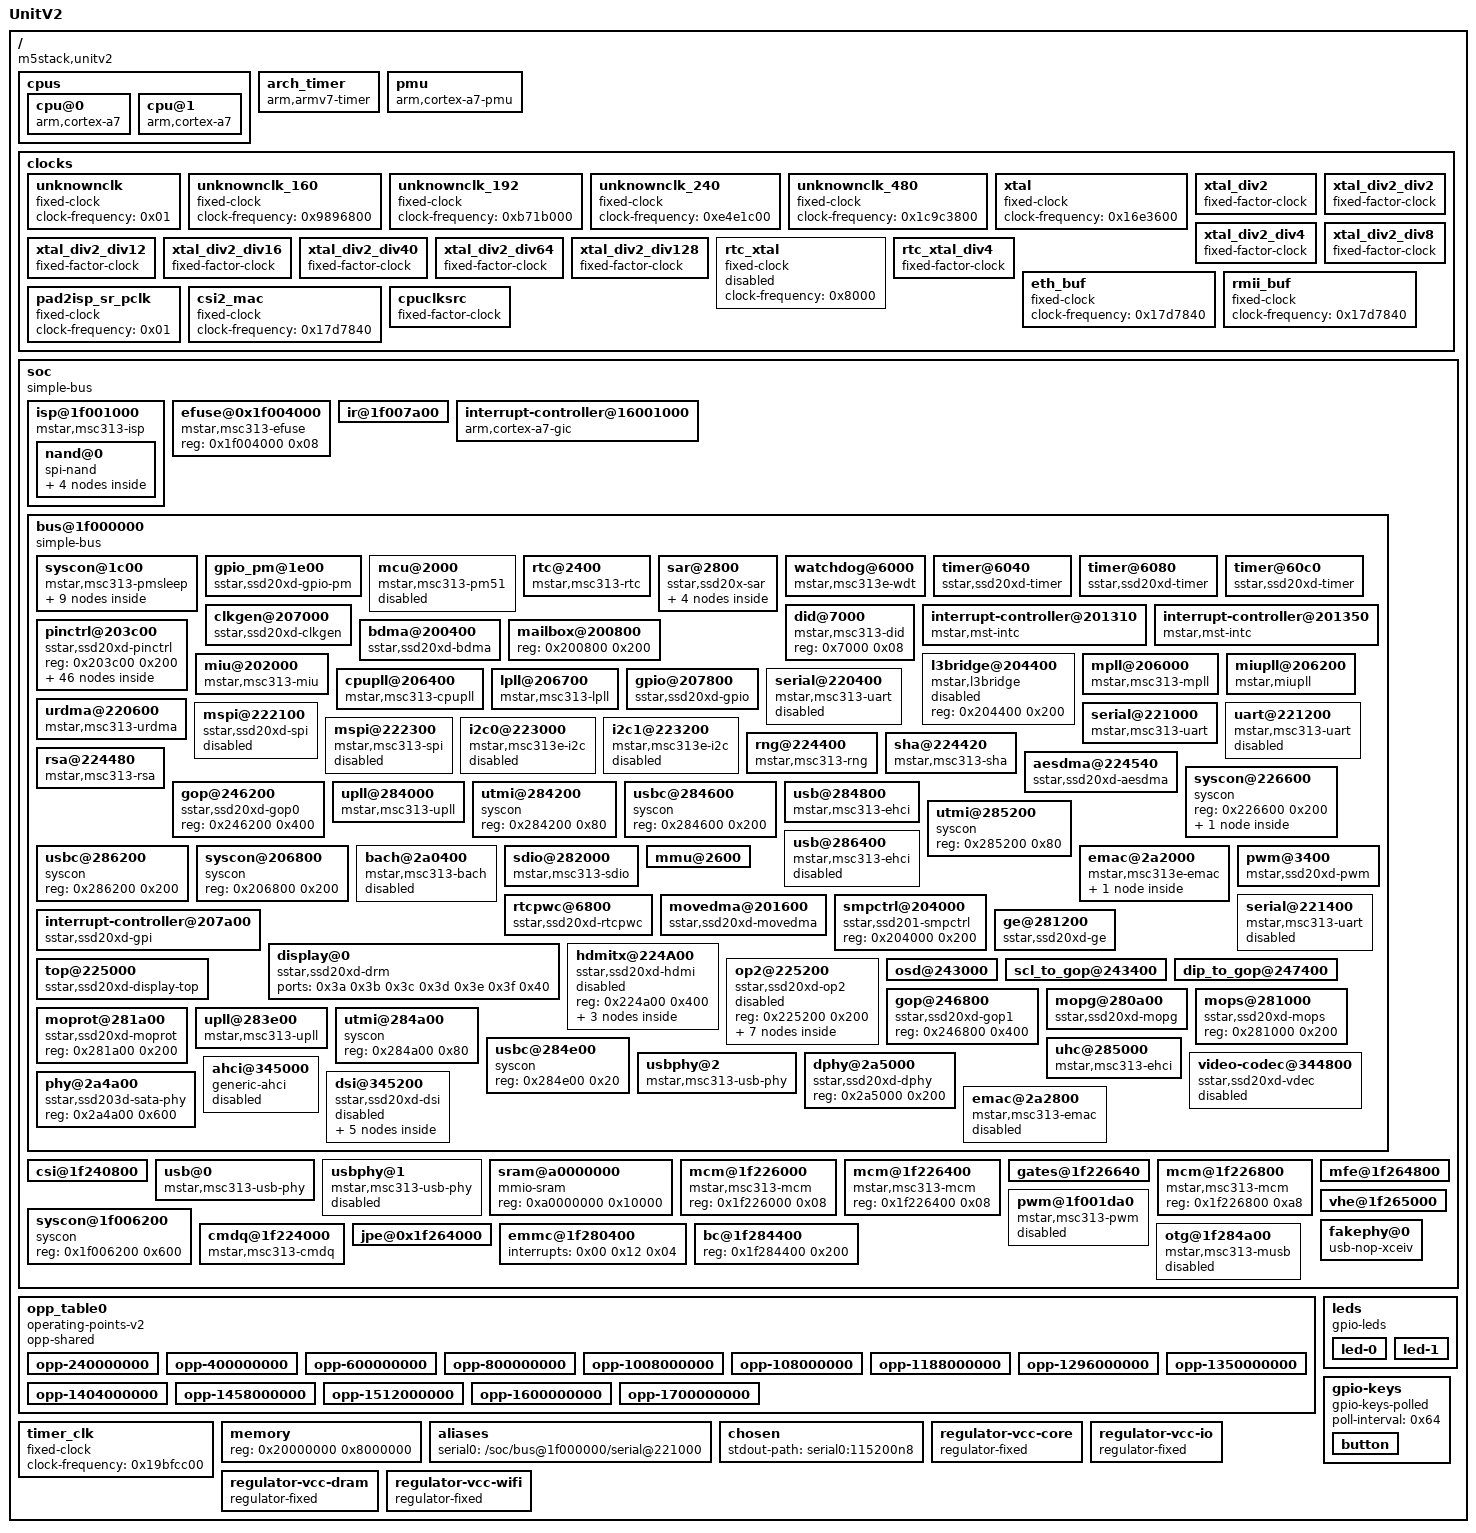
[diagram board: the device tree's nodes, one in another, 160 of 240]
/dts-v1/;

/ {
	#address-cells = <0x01>;
	#size-cells = <0x01>;
	interrupt-parent = <0x01>;
	model = "UnitV2";
	compatible = "m5stack,unitv2\0mstar,infinity2m";

	cpus {
		#address-cells = <0x01>;
		#size-cells = <0x00>;

		cpu@0 {
			device_type = "cpu";
			compatible = "arm,cortex-a7";
			reg = <0x00>;
			clocks = <0x02>;
			clock-names = "cpuclk";
			operating-points-v2 = <0x03>;
			cpu-supply = <0x04>;
			phandle = <0x05>;
		};

		cpu@1 {
			device_type = "cpu";
			compatible = "arm,cortex-a7";
			operating-points-v2 = <0x03>;
			reg = <0x01>;
			clocks = <0x02>;
			clock-names = "cpuclk";
			phandle = <0x06>;
		};
	};

	arch_timer {
		compatible = "arm,armv7-timer";
		interrupts = <0x01 0x0d 0x308 0x01 0x0e 0x308 0x01 0x0b 0x308 0x01 0x0a 0x308>;
		clock-frequency = <0x5b8d80>;
		arm,cpu-registers-not-fw-configured;
	};

	pmu {
		compatible = "arm,cortex-a7-pmu";
		interrupts = <0x00 0x0a 0x04 0x00 0x10 0x04>;
		interrupt-affinity = <0x05 0x06>;
	};

	clocks {

		unknownclk {
			#clock-cells = <0x00>;
			compatible = "fixed-clock";
			clock-frequency = <0x01>;
			phandle = <0x22>;
		};

		unknownclk_160 {
			#clock-cells = <0x00>;
			compatible = "fixed-clock";
			clock-frequency = <0x9896800>;
			phandle = <0x1e>;
		};

		unknownclk_192 {
			#clock-cells = <0x00>;
			compatible = "fixed-clock";
			clock-frequency = <0xb71b000>;
			phandle = <0x1f>;
		};

		unknownclk_240 {
			#clock-cells = <0x00>;
			compatible = "fixed-clock";
			clock-frequency = <0xe4e1c00>;
			phandle = <0x20>;
		};

		unknownclk_480 {
			#clock-cells = <0x00>;
			compatible = "fixed-clock";
			clock-frequency = <0x1c9c3800>;
			phandle = <0x21>;
		};

		xtal {
			#clock-cells = <0x00>;
			compatible = "fixed-clock";
			clock-frequency = <0x16e3600>;
			phandle = <0x07>;
		};

		xtal_div2 {
			#clock-cells = <0x00>;
			compatible = "fixed-factor-clock";
			clocks = <0x07>;
			clock-div = <0x02>;
			clock-mult = <0x01>;
			phandle = <0x08>;
		};

		xtal_div2_div2 {
			compatible = "fixed-factor-clock";
			#clock-cells = <0x00>;
			clocks = <0x08>;
			clock-div = <0x02>;
			clock-mult = <0x01>;
		};

		xtal_div2_div4 {
			compatible = "fixed-factor-clock";
			#clock-cells = <0x00>;
			clocks = <0x08>;
			clock-div = <0x04>;
			clock-mult = <0x01>;
		};

		xtal_div2_div8 {
			compatible = "fixed-factor-clock";
			#clock-cells = <0x00>;
			clocks = <0x08>;
			clock-div = <0x08>;
			clock-mult = <0x01>;
			phandle = <0x15>;
		};

		xtal_div2_div12 {
			compatible = "fixed-factor-clock";
			#clock-cells = <0x00>;
			clocks = <0x08>;
			clock-div = <0x0c>;
			clock-mult = <0x01>;
			phandle = <0x16>;
		};

		xtal_div2_div16 {
			compatible = "fixed-factor-clock";
			#clock-cells = <0x00>;
			clocks = <0x08>;
			clock-div = <0x10>;
			clock-mult = <0x01>;
			phandle = <0x17>;
		};

		xtal_div2_div40 {
			compatible = "fixed-factor-clock";
			#clock-cells = <0x00>;
			clocks = <0x08>;
			clock-div = <0x28>;
			clock-mult = <0x01>;
			phandle = <0x1c>;
		};

		xtal_div2_div64 {
			compatible = "fixed-factor-clock";
			#clock-cells = <0x00>;
			clocks = <0x08>;
			clock-div = <0x40>;
			clock-mult = <0x01>;
		};

		xtal_div2_div128 {
			compatible = "fixed-factor-clock";
			#clock-cells = <0x00>;
			clocks = <0x08>;
			clock-div = <0x80>;
			clock-mult = <0x01>;
		};

		rtc_xtal {
			#clock-cells = <0x00>;
			compatible = "fixed-clock";
			clock-frequency = <0x8000>;
			status = "disabled";
			phandle = <0x09>;
		};

		rtc_xtal_div4 {
			compatible = "fixed-factor-clock";
			#clock-cells = <0x00>;
			clocks = <0x09>;
			clock-div = <0x04>;
			clock-mult = <0x01>;
			phandle = <0x14>;
		};

		eth_buf {
			#clock-cells = <0x00>;
			compatible = "fixed-clock";
			clock-frequency = <0x17d7840>;
			phandle = <0x2c>;
		};

		rmii_buf {
			#clock-cells = <0x00>;
			compatible = "fixed-clock";
			clock-frequency = <0x17d7840>;
			phandle = <0x2d>;
		};

		pad2isp_sr_pclk {
			#clock-cells = <0x00>;
			compatible = "fixed-clock";
			clock-frequency = <0x01>;
		};

		csi2_mac {
			#clock-cells = <0x00>;
			compatible = "fixed-clock";
			clock-frequency = <0x17d7840>;
		};

		cpuclksrc {
			compatible = "fixed-factor-clock";
			#clock-cells = <0x00>;
			clocks = <0x0a 0x01>;
			clock-div = <0x01>;
			clock-mult = <0x01>;
			phandle = <0x0c>;
		};
	};

	soc {
		compatible = "simple-bus";
		#address-cells = <0x01>;
		#size-cells = <0x01>;
		ranges = <0x14000000 0x14000000 0x1000000 0x16001000 0x16001000 0x7000 0x1f000000 0x1f000000 0x400000 0xa0000000 0xa0000000 0x20000>;

		isp@1f001000 {
			#address-cells = <0x01>;
			#size-cells = <0x00>;
			compatible = "mstar,msc313-isp";
			reg = <0x1f001000 0x400 0x1f002c00 0x200 0x1f002e00 0x200 0x14000000 0x1000000>;
			clock-names = "pm_spi\0cpuclk\0spi";
			clocks = <0x0b 0x03 0x0c 0x0d 0x01 0x04 0x00>;
			interrupts-extended = <0x0e 0x00 0x05 0x04>;
			dmas = <0x0f 0x00>;
			dma-names = "qspi";
			pinctrl-names = "default";
			pinctrl-0 = <0x10>;
			status = "okay";
			interconnects = <0x11 0x00>;
			interconnect-names = "dma-mem";

			nand@0 {
				#address-cells = <0x01>;
				#size-cells = <0x01>;
				compatible = "spi-nand";
				reg = <0x00>;
				spi-max-frequency = <0x2625a00>;
				spi-rx-bus-width = <0x04>;

				partitions {
					compatible = "fixed-partitions";
					#address-cells = <0x01>;
					#size-cells = <0x01>;

					uboot-spl@200000 {
						label = "uboot-spl";
						reg = <0x200000 0x60000>;
					};

					ubi@ec0000 {
						label = "ubi";
						reg = <0xec0000 0x60000>;
					};
					data@f20000 {
						label = "data";
						reg = <0xf20000 0x10e0000>;
					};
				};
			};
		};

		efuse@0x1f004000 {
			compatible = "mstar,msc313-efuse";
			reg = <0x1f004000 0x08>;
		};

		ir@1f007a00 {
			interrupts-extended = <0x12 0x00 0x03 0x04 0x12 0x00 0x04 0x04>;
		};

		interrupt-controller@16001000 {
			compatible = "arm,cortex-a7-gic";
			reg = <0x16001000 0x1000 0x16002000 0x2000 0x16004000 0x2000 0x16006000 0x2000>;
			#interrupt-cells = <0x03>;
			interrupt-controller;
			interrupts = <0x01 0x09 0x308>;
			phandle = <0x01>;
		};

		bus@1f000000 {
			compatible = "simple-bus";
			reg = <0x1f000000 0x400000>;
			#address-cells = <0x01>;
			#size-cells = <0x01>;
			ranges = <0x00 0x1f000000 0x400000>;
			interrupts-extended = <0x0e 0x00 0x33 0x04>;

			syscon@1c00 {
				compatible = "mstar,msc313-pmsleep\0syscon\0simple-mfd";
				reg = <0x1c00 0x100>;
				use-raw-spinlock;
				phandle = <0x13>;

				pinctrl {
					compatible = "sstar,ssd20xd-pm-pinctrl";
					phandle = <0x19>;

					pm_uart {
						function = "pm_uart";
						groups = "pm_uart";
						phandle = <0x28>;
					};

					pm_spi {
						function = "pm_spi";
						groups = "pm_spi";
						phandle = <0x10>;
					};

					pm_irin {
						function = "pm_irin";
						groups = "pm_irin";
					};

					pm_led_mode1 {
						function = "pm_led";
						groups = "pm_led_mode1";
					};
				};

				interrupt-controller@1c10 {
					compatible = "mstar,msc313-pm-intc";
					interrupt-parent = <0x0e>;
					interrupts = <0x00 0x02 0x04>;
					interrupt-controller;
					#interrupt-cells = <0x01>;
					phandle = <0x18>;
				};

				interrupt-controller@1c20 {
					compatible = "mstar,msc313-pm-wakeup-intc";
					interrupt-parent = <0x0e>;
					interrupts = <0x00 0x02 0x04>;
					interrupt-controller;
					#interrupt-cells = <0x02>;
					mstar,pmsleep = <0x13>;
					phandle = <0x1a>;
				};

				pm_muxes@0 {
					compatible = "mstar,msc313-pm-muxes";
					#clock-cells = <0x01>;
					clock-names = "rtc_xtal\0rtc_xtal_div4\0xtal_div2\0xtal_div2_div8\0xtal_div2_div12\0xtal_div2_div16\0mpll_div_4";
					clocks = <0x09 0x14 0x08 0x15 0x16 0x17 0x0a 0x03>;
					phandle = <0x0b>;
				};

				reboot {
					compatible = "syscon-reboot";
					offset = <0xb8>;
					mask = <0x79>;
				};
			};

			gpio_pm@1e00 {
				reg = <0x1e00 0x200>;
				#gpio-cells = <0x02>;
				gpio-controller;
				interrupt-controller;
				#interrupt-cells = <0x03>;
				interrupt-parent = <0x18>;
				status = "okay";
				compatible = "sstar,ssd20xd-gpio-pm";
				gpio-ranges = <0x19 0x00 0x20 0x01 0x19 0x01 0x5b 0x01 0x19 0x02 0x67 0x01 0x19 0x02 0x68 0x01>;
				phandle = <0x35>;
			};

			mcu@2000 {
				compatible = "mstar,msc313-pm51";
				reg = <0x2000 0x200>;
				mstar,pmsleep = <0x13>;
				dma-names = "bdma0\0bdma1";
				dmas = <0x0f 0x00 0x0f 0x01>;
				interconnects = <0x11 0x00>;
				interconnect-names = "dma-mem";
				interrupts-extended = <0x12 0x00 0x11 0x04>;
				status = "disabled";
			};

			rtc@2400 {
				compatible = "mstar,msc313-rtc";
				reg = <0x2400 0x40>;
				clocks = <0x0b 0x07>;
				interrupts-extended = <0x0e 0x00 0x2c 0x04 0x1a 0x04 0x04>;
				wakeup-source;
			};

			sar@2800 {
				reg = <0x2800 0x200>;
				interrupts-extended = <0x0e 0x00 0x2d 0x04 0x1a 0x01 0x04 0x1a 0x06 0x04 0x12 0x00 0x18 0x04 0x12 0x00 0x19 0x04 0x12 0x00 0x1a 0x04 0x12 0x00 0x1b 0x04>;
				interrupt-names = "sar\0wakeup\0wakeup_gpio\0sar_gpio0\0sar_gpio1\0sar_gpio2\0sar_gpio3";
				clock-names = "sar_clk";
				clocks = <0x0b 0x09>;
				#gpio-cells = <0x02>;
				mstar,pmsleep = <0x13>;
				wakeup-source;
				status = "okay";
				compatible = "sstar,ssd20x-sar";

				sar0_gpio0 {
					function = "sar0";
					groups = "sar_gpio0";
				};

				sar1_gpio1 {
					function = "sar1";
					groups = "sar_gpio1";
				};

				sar2_gpio2 {
					function = "sar2";
					groups = "sar_gpio2";
				};

				sar3_gpio3 {
					function = "sar3";
					groups = "sar_gpio3";
				};
			};

			watchdog@6000 {
				compatible = "mstar,msc313e-wdt";
				reg = <0x6000 0x1f>;
				clocks = <0x08>;
				interrupts-extended = <0x12 0x00 0x02 0x04>;
			};

			timer@6040 {
				compatible = "sstar,ssd20xd-timer";
				reg = <0x6040 0x40>;
				clocks = <0x1b>;
				interrupts-extended = <0x12 0x00 0x00 0x04>;
			};

			timer@6080 {
				compatible = "sstar,ssd20xd-timer";
				reg = <0x6080 0x40>;
				clocks = <0x1b>;
				interrupts-extended = <0x12 0x00 0x01 0x04>;
			};

			timer@60c0 {
				compatible = "sstar,ssd20xd-timer";
				reg = <0x60c0 0x40>;
				clocks = <0x1b>;
				interrupts-extended = <0x12 0x00 0x0c 0x04>;
			};

			clkgen@207000 {
				compatible = "sstar,ssd20xd-clkgen";
				reg = <0x207000 0x200>;
				#clock-cells = <0x03>;
				clock-names = "deglitch\0xtal_div2\0xtal_div2_div40\0gate0\0gate1\0gate2\0gate3\0gate4\0gate5\0gate6\0gate7\0gate8\0gate9\0gate10\0gate11\0gate12\0gate13\0gate14\0gate15\0miupll\0lpll";
				clocks = <0x08 0x08 0x1c 0x1d 0x00 0x1d 0x01 0x1e 0x1f 0x20 0x21 0x0a 0x01 0x22 0x0a 0x02 0x0a 0x03 0x0a 0x04 0x0a 0x05 0x0a 0x06 0x22 0x0a 0x07 0x22 0x23 0x24 0x00>;
				phandle = <0x0d>;
			};

			did@7000 {
				compatible = "mstar,msc313-did";
				reg = <0x7000 0x08>;
			};

			interrupt-controller@201310 {
				compatible = "mstar,mst-intc";
				reg = <0x201310 0x40>;
				#interrupt-cells = <0x03>;
				interrupt-controller;
				interrupt-parent = <0x01>;
				mstar,irqs-map-range = <0x60 0x7f>;
				phandle = <0x12>;
			};

			interrupt-controller@201350 {
				compatible = "mstar,mst-intc";
				reg = <0x201350 0x40>;
				#interrupt-cells = <0x03>;
				interrupt-controller;
				interrupt-parent = <0x01>;
				mstar,irqs-map-range = <0x20 0x5f>;
				mstar,intc-no-eoi;
				phandle = <0x0e>;
			};

			pinctrl@203c00 {
				reg = <0x203c00 0x200>;
				compatible = "sstar,ssd20xd-pinctrl";

				eth {
					function = "eth";
					groups = "eth_mode1";
					phandle = <0x37>;
				};

				eth1_mode4 {
					function = "eth1";
					groups = "eth1_mode4";
				};

				fuart {
					function = "fuart";
					groups = "fuart";
					phandle = <0x27>;
				};

				fuart_mode1 {
					function = "fuart";
					groups = "fuart_mode1";
				};

				fuart_mode2 {
					function = "fuart";
					groups = "fuart_mode2";
				};

				fuart_mode3 {
					function = "fuart";
					groups = "fuart_mode3";
				};

				fuart_mode4 {
					function = "fuart";
					groups = "fuart_mode4";
				};

				fuart_mode5 {
					function = "fuart";
					groups = "fuart_mode5";
				};

				fuart_mode6 {
					function = "fuart";
					groups = "fuart_mode6";
				};

				fuart_mode7 {
					function = "fuart";
					groups = "fuart_mode7";
				};

				fuart_rx_tx_rts {
					function = "fuart";
					groups = "fuart_rx_tx_rts";
				};

				uart1_mode1 {
					function = "uart1";
					groups = "uart1_mode1";
				};

				uart1 {
					function = "uart1";
					groups = "fuart_cts_rts";
					phandle = <0x29>;
				};

				uart1_cts {
					function = "uart1";
					groups = "fuart_cts";
				};

				i2c0 {
					function = "i2c0";
					groups = "i2c0";
				};

				i2c0_mode1 {
					function = "i2c0";
					groups = "i2c0_mode1";
				};

				i2c0_mode4 {
					function = "i2c0";
					groups = "i2c0_mode4";
				};

				i2c1 {
					function = "i2c1";
					groups = "i2c1";
					phandle = <0x2b>;
				};

				i2c1_mode1 {
					function = "i2c1";
					groups = "i2c1_mode1";
				};

				i2c1_mode3 {
					function = "i2c1";
					groups = "i2c1_mode3";
				};

				i2c1_mode4 {
					function = "i2c1";
					groups = "i2c1_mode4";
				};

				i2c1_mode5 {
					function = "i2c1";
					groups = "i2c1_mode5";
				};

				spi0_spi0 {
					function = "spi0";
					groups = "spi0";
				};

				spi0_fuart {
					function = "spi0";
					groups = "fuart";
				};

				spi0_mode5 {
					function = "spi0";
					groups = "spi0_mode5";
				};

				spi1_sd_d0_d1_d2_d3 {
					function = "spi1";
					groups = "sd_d0_d1_d2_d3";
				};

				sdio {
					function = "sdio";
					groups = "sdio_mode1";
					bias-pull-up;
					phandle = <0x34>;
				};

				sdio_mode1_4ma_pins {
					function = "sdio";
					groups = "sdio_mode1";
					bias-pull-up;
					drive-strength = <0x04>;
				};

				sdio_mode1_8ma_pins {
					function = "sdio";
					groups = "sdio_mode1";
					bias-pull-up;
					drive-strength = <0x08>;
				};

				usb {
					function = "usb";
					groups = "usb";
				};

				usb1 {
					function = "usb1";
					groups = "usb1";
				};

				pwm0_mode1 {
					function = "pwm0";
					groups = "pwm0_mode1";
				};

				pwm0_mode2 {
					function = "pwm0";
					groups = "pwm0_mode2";
				};

				pwm0_mode3 {
					function = "pwm0";
					groups = "pwm0_mode3";
				};

				pwm0_mode4 {
					function = "pwm0";
					groups = "pwm0_mode4";
				};

				pwm1_mode4 {
					function = "pwm1";
					groups = "pwm1_mode4";
				};

				pwm1_fuart_tx {
					function = "pwm1";
					groups = "fuart_tx";
				};

				pwm2_fuart_cts {
					function = "pwm2";
					groups = "fuart_cts";
				};

				pwm3_fuart_rts {
					function = "pwm3";
					groups = "fuart_rts";
				};

				pwm4_spi0_cz {
					function = "pwm4";
					groups = "spi0_cz";
				};

				pwm5_spi0_ck {
					function = "pwm5";
					groups = "spi0_ck";
				};

				pwm6_spi_di {
					function = "pwm6";
					groups = "spi0_di";
				};

				pwm7_spi_do {
					function = "pwm7";
					groups = "spi0_do";
				};

				ttl_mode1 {
					function = "ttl";
					groups = "ttl_mode1";
				};

				tx_mipi_mode1 {
					function = "tx_mipi";
					groups = "tx_mipi_mode1";
				};

				tx_mipi_mode2 {
					function = "tx_mipi";
					groups = "tx_mipi_mode2";
				};
			};

			bdma@200400 {
				compatible = "sstar,ssd20xd-bdma";
				reg = <0x200400 0x100>;
				interrupt-parent = <0x0e>;
				interrupts = <0x00 0x28 0x04 0x00 0x29 0x04 0x00 0x3d 0x04 0x00 0x3e 0x04>;
				clocks = <0x0d 0x01 0x0d 0x00>;
				dma-channels = <0x02>;
				status = "okay";
				#dma-cells = <0x01>;
				phandle = <0x0f>;
			};

			mailbox@200800 {
				reg = <0x200800 0x200>;
			};

			miu@202000 {
				compatible = "mstar,msc313-miu";
				reg = <0x202000 0x200 0x202400 0x200 0x202200 0x200>;
				interrupt-parent = <0x0e>;
				interrupts = <0x00 0x31 0x04>;
				clock-names = "miu\0ddr";
				clocks = <0x0d 0x01 0x00 0x00 0x0d 0x01 0x01 0x00>;
				mstar,trcd = <0x06>;
				mstar,trp = <0x06>;
				#clock-cells = <0x00>;
				clock-output-names = "ddrpll";
				dma-ranges = <0x00 0x20000000 0x10000000>;
				#interconnect-cells = <0x01>;
				ddr-supply = <0x25>;
				phandle = <0x11>;
			};

			l3bridge@204400 {
				compatible = "mstar,l3bridge\0syscon";
				reg = <0x204400 0x200>;
				status = "disabled";
			};

			mpll@206000 {
				compatible = "mstar,msc313-mpll";
				#clock-cells = <0x01>;
				reg = <0x206000 0x200>;
				clocks = <0x07>;
				phandle = <0x0a>;
			};

			miupll@206200 {
				compatible = "mstar,miupll";
				reg = <0x206200 0x200>;
				#clock-cells = <0x00>;
				clocks = <0x07>;
				phandle = <0x23>;
			};

			cpupll@206400 {
				compatible = "mstar,msc313-cpupll";
				reg = <0x206400 0x200>;
				#clock-cells = <0x00>;
				clocks = <0x0c>;
				phandle = <0x02>;
			};

			lpll@206700 {
				compatible = "mstar,msc313-lpll";
				reg = <0x206700 0x100>;
				#clock-cells = <0x01>;
				clocks = <0x0a 0x01>;
				phandle = <0x24>;
			};

			gpio@207800 {
				#gpio-cells = <0x02>;
				reg = <0x207800 0x200>;
				gpio-controller;
				#interrupt-cells = <0x02>;
				interrupt-controller;
				interrupt-parent = <0x26>;
				status = "okay";
				compatible = "sstar,ssd20xd-gpio";
				phandle = <0x4c>;
			};

			serial@220400 {
				compatible = "mstar,msc313-uart";
				reg = <0x220400 0x100>;
				interrupt-parent = <0x0e>;
				interrupts = <0x00 0x2f 0x04>;
				reg-shift = <0x03>;
				clocks = <0x0d 0x01 0x08 0x00>;
				pinctrl-names = "default";
				pinctrl-0 = <0x27>;
				status = "disabled";
			};

			urdma@220600 {
				compatible = "mstar,msc313-urdma";
				reg = <0x220600 0x100>;
				interrupts-extended = <0x0e 0x00 0x30 0x04>;
				clocks = <0x11 0x00>;
			};

			serial@221000 {
				compatible = "mstar,msc313-uart\0snps,dw-apb-uart";
				reg = <0x221000 0x100>;
				reg-shift = <0x03>;
				interrupts-extended = <0x0e 0x00 0x22 0x04>;
				clocks = <0x0d 0x01 0x02 0x00>;
				pinctrl-names = "default";
				pinctrl-0 = <0x28>;
				status = "okay";
			};

			uart@221200 {
				compatible = "mstar,msc313-uart\0snps,dw-apb-uart";
				reg = <0x221200 0x100>;
				reg-shift = <0x03>;
				interrupts-extended = <0x0e 0x00 0x23 0x04>;
				clocks = <0x0d 0x01 0x03 0x00>;
				status = "disabled";
				pinctrl-names = "default";
				pinctrl-0 = <0x29>;
			};

			mspi@222100 {
				compatible = "sstar,ssd20xd-spi\0mstar,msc313-spi";
				reg = <0x222100 0x100>;
				interrupt-parent = <0x0e>;
				interrupts = <0x00 0x26 0x04>;
				clocks = <0x0d 0x01 0x05 0x00>;
				status = "disabled";
				dma-names = "movedma";
				dmas = <0x2a 0x00>;
			};

			mspi@222300 {
				compatible = "mstar,msc313-spi";
				reg = <0x222300 0x100>;
				interrupt-parent = <0x0e>;
				interrupts = <0x00 0x27 0x04>;
				clocks = <0x0d 0x01 0x06 0x00>;
				status = "disabled";
			};

			i2c0@223000 {
				compatible = "mstar,msc313e-i2c";
				reg = <0x223000 0x200>;
				interrupts-extended = <0x0e 0x00 0x24 0x04>;
				#address-cells = <0x01>;
				#size-cells = <0x00>;
				clock-names = "i2c_clk";
				clocks = <0x0d 0x01 0x09 0x00>;
				interconnect-names = "dma-mem";
				interconnects = <0x11 0x00>;
				status = "disabled";
			};

			i2c1@223200 {
				compatible = "mstar,msc313e-i2c";
				reg = <0x223200 0x200>;
				interrupts-extended = <0x0e 0x00 0x25 0x04>;
				#address-cells = <0x01>;
				#size-cells = <0x00>;
				clock-names = "i2c_clk";
				clocks = <0x0d 0x01 0x0a 0x00>;
				pinctrl-names = "default";
				pinctrl-0 = <0x2b>;
				interconnect-names = "dma-mem";
				interconnects = <0x11 0x00>;
				status = "disabled";
			};

			rng@224400 {
				compatible = "mstar,msc313-rng";
				reg = <0x224400 0x10>;
				clocks = <0x0d 0x01 0x00 0x00>;
			};

			sha@224420 {
				reg = <0x224420 0x60>;
				compatible = "mstar,msc313-sha";
				clocks = <0x0d 0x01 0x0e 0x00>;
				interconnects = <0x11 0x00>;
				interconnect-names = "dma-mem";
			};

			rsa@224480 {
				reg = <0x224480 0xc0>;
				compatible = "mstar,msc313-rsa";
				clocks = <0x0d 0x01 0x0e 0x00>;
				interconnects = <0x11 0x00>;
				interconnect-names = "dma-mem";
			};

			aesdma@224540 {
				reg = <0x224540 0xc0>;
				compatible = "sstar,ssd20xd-aesdma";
				clocks = <0x0d 0x01 0x0e 0x00>;
				interconnects = <0x11 0x00>;
				interconnect-names = "dma-mem";
			};

			syscon@226600 {
				compatible = "syscon\0simple-mfd";
				#address-cells = <0x01>;
				#size-cells = <0x00>;
				reg = <0x226600 0x200>;

				sc_gp_ctrl_muxes@0 {
					#clock-cells = <0x01>;
					compatible = "sstar,ssd20xd-sc-gp-ctrl-muxes";
					clock-names = "eth_buf\0rmii_buf\0xtal_div2\0sdio_clkgen\0sc_pixel";
					clocks = <0x2c 0x2d 0x08 0x0d 0x01 0x0c 0x00 0x0d 0x01 0x18 0x00>;
					phandle = <0x33>;
				};
			};

			gop@246200 {
				reg = <0x246200 0x400>;
				interrupt-names = "gop";
				status = "okay";
				compatible = "sstar,ssd20xd-gop0";
				phandle = <0x3c>;
			};

			upll@284000 {
				#clock-cells = <0x01>;
				compatible = "mstar,msc313-upll";
				reg = <0x284000 0x20>;
				clocks = <0x07>;
				phandle = <0x1d>;
			};

			utmi@284200 {
				compatible = "syscon";
				reg = <0x284200 0x80>;
				phandle = <0x49>;
			};

			usbc@284600 {
				compatible = "syscon";
				reg = <0x284600 0x200>;
				phandle = <0x2f>;
			};

			usb@284800 {
				compatible = "mstar,msc313-ehci\0faraday,fusbh200";
				reg = <0x284800 0x200>;
				interrupts-extended = <0x0e 0x00 0x37 0x04>;
				phys = <0x2e 0x00>;
				phy-names = "usb";
				mstar,usbc = <0x2f>;
				interconnect-names = "dma-mem";
				interconnects = <0x11 0x00>;
				status = "okay";
			};

			utmi@285200 {
				compatible = "syscon";
				reg = <0x285200 0x80>;
				phandle = <0x4a>;
			};

			usbc@286200 {
				compatible = "syscon";
				reg = <0x286200 0x200>;
				phandle = <0x31>;
			};

			usb@286400 {
				compatible = "mstar,msc313-ehci\0faraday,fusbh200";
				reg = <0x286400 0x200>;
				interrupts-extended = <0x0e 0x00 0x1f 0x04>;
				phys = <0x30 0x00>;
				phy-names = "usb";
				mstar,usbc = <0x31>;
				interconnect-names = "dma-mem";
				interconnects = <0x11 0x00>;
				status = "disabled";
			};

			syscon@206800 {
				compatible = "syscon";
				reg = <0x206800 0x200>;
				phandle = <0x32>;
			};

			bach@2a0400 {
				compatible = "mstar,msc313-bach";
				reg = <0x2a0400 0x600>;
				clocks = <0x0d 0x02 0x00 0x00>;
				interrupt-parent = <0x0e>;
				interrupts = <0x00 0x2a 0x04>;
				interconnect-names = "dma-mem";
				interconnects = <0x11 0x00>;
				mstar,audiotop = <0x32>;
				status = "disabled";
			};

			sdio@282000 {
				compatible = "mstar,msc313-sdio";
				interrupts-extended = <0x0e 0x00 0x13 0x04>;
				clocks = <0x33 0x11>;
				reg = <0x282000 0x200>;
				no-1-8-v;
				cap-sd-highspeed;
				bus-width = <0x04>;
				pinctrl-names = "default";
				pinctrl-0 = <0x34>;
				interconnects = <0x11 0x00>;
				interconnect-names = "dma-mem";
				status = "okay";
				cd-gpios = <0x35 0x01 0x01>;
				vmmc-supply = <0x36>;
				vqmmc-supply = <0x36>;
			};

			emac@2a2000 {
				#address-cells = <0x01>;
				#size-cells = <0x00>;
				compatible = "mstar,msc313e-emac";
				interrupts-extended = <0x0e 0x00 0x1a 0x04>;
				reg = <0x2a2000 0x400 0x343c00 0x400>;
				phy-mode = "mii";
				clock-names = "pclk\0hclk\0tx_clk\0rx_clk";
				clocks = <0x0d 0x01 0x0b 0x00 0x0d 0x01 0x0b 0x00 0x33 0x05 0x33 0x01>;
				assigned-clocks = <0x33 0x00 0x33 0x04>;
				assigned-clock-parents = <0x2c 0x2c>;
				pinctrl-names = "default";
				pinctrl-0 = <0x37>;
				local-mac-address = [00 00 00 00 00 00];
				status = "okay";
				interconnects = <0x11 0x00>;
				interconnect-names = "dma-mem";
				phy-handle = <0x38>;

				phy@0 {
					compatible = "ethernet-phy-idDEAD.B33F";
					phy-is-integrated;
					reg = <0x00>;
					mstar,pmsleep = <0x13>;
					mstar,phyana = <0x39>;
					interrupts-extended = <0x12 0x00 0x15 0x04>;
					phandle = <0x38>;
				};
			};

			mmu@2600 {
			};

			pwm@3400 {
				compatible = "mstar,ssd20xd-pwm";
				reg = <0x3400 0x400>;
				#pwm-cells = <0x02>;
				clocks = <0x08>;
			};

			rtcpwc@6800 {
				compatible = "sstar,ssd20xd-rtcpwc";
				reg = <0x6800 0x200>;
				interrupts-extended = <0x1a 0x07 0x04>;
				wakeup-source;
			};

			movedma@201600 {
				compatible = "sstar,ssd20xd-movedma";
				#dma-cells = <0x01>;
				reg = <0x201600 0x200>;
				interrupts-extended = <0x0e 0x00 0x3c 0x04>;
				phandle = <0x2a>;
			};

			smpctrl@204000 {
				reg = <0x204000 0x200>;
				status = "okay";
				compatible = "sstar,ssd201-smpctrl\0mstar,smpctrl";
			};

			serial@221400 {
				compatible = "mstar,msc313-uart\0snps,dw-apb-uart";
				reg = <0x221400 0x100>;
				reg-shift = <0x03>;
				interrupts-extended = <0x0e 0x00 0x27 0x04>;
				status = "disabled";
			};

			interrupt-controller@207a00 {
				compatible = "sstar,ssd20xd-gpi";
				reg = <0x207a00 0x200>;
				#interrupt-cells = <0x02>;
				interrupt-controller;
				interrupts-extended = <0x0e 0x00 0x38 0x04>;
				phandle = <0x26>;
			};

			display@0 {
				compatible = "sstar,ssd20xd-drm";
				ports = <0x3a 0x3b 0x3c 0x3d 0x3e 0x3f 0x40>;
			};

			ge@281200 {
				compatible = "sstar,ssd20xd-ge";
				reg = <0x281200 0x200>;
				clocks = <0x0d 0x01 0x11 0x00>;
				clock-names = "ge";
				interrupts-extended = <0x0e 0x00 0x19 0x04>;
				interconnects = <0x11 0x00>;
				interconnect-names = "dma-mem";
			};

			hdmitx@224A00 {
				compatible = "sstar,ssd20xd-hdmi";
				reg = <0x224a00 0x400>;
				status = "disabled";

				ports {
					#address-cells = <0x01>;
					#size-cells = <0x00>;

					port@0 {
						reg = <0x00>;

						endpoint {
							remote-endpoint = <0x41>;
						};
					};
				};
			};

			top@225000 {
				compatible = "sstar,ssd20xd-display-top";
				reg = <0x225000 0x200>;
				interrupts-extended = <0x0e 0x00 0x32 0x04>;
				clock-names = "sc_pixel\0disp_432\0disp_216\0hdmi";
				clocks = <0x0d 0x01 0x18 0x00 0x0d 0x01 0x19 0x00 0x0d 0x01 0x1a 0x00 0x33 0x13>;
				phandle = <0x3f>;
			};

			op2@225200 {
				compatible = "sstar,ssd20xd-op2";
				reg = <0x225200 0x200>;
				status = "disabled";
				phandle = <0x3e>;

				ports {
					#address-cells = <0x01>;
					#size-cells = <0x00>;

					port@0 {
						reg = <0x00>;

						endpoint {
						};
					};

					port@1 {
						reg = <0x01>;

						endpoint {
							phandle = <0x48>;
						};
					};

					port@2 {
						reg = <0x02>;

						endpoint {
							phandle = <0x41>;
						};
					};
				};
			};

			osd@243000 {
			};

			scl_to_gop@243400 {
			};

			dip_to_gop@247400 {
			};

			gop@246800 {
				compatible = "sstar,ssd20xd-gop1";
				reg = <0x246800 0x400>;
				phandle = <0x3d>;
			};

			mopg@280a00 {
				compatible = "sstar,ssd20xd-mopg";
				reg = <0x280a00 0x600>;
				clocks = <0x0d 0x01 0x12 0x00>;
				phandle = <0x3a>;
			};

			mops@281000 {
				compatible = "sstar,ssd20xd-mops";
				reg = <0x281000 0x200>;
				phandle = <0x3b>;
			};

			moprot@281a00 {
				compatible = "sstar,ssd20xd-moprot";
				reg = <0x281a00 0x200>;
			};

			upll@283e00 {
				#clock-cells = <0x01>;
				compatible = "mstar,msc313-upll";
				reg = <0x283e00 0x20>;
				clocks = <0x07>;
			};

			utmi@284a00 {
				compatible = "syscon";
				reg = <0x284a00 0x80>;
				phandle = <0x42>;
			};

			usbc@284e00 {
				compatible = "syscon";
				reg = <0x284e00 0x20>;
				phandle = <0x43>;
			};

			usbphy@2 {
				#phy-cells = <0x01>;
				compatible = "mstar,msc313-usb-phy";
				clocks = <0x08>;
				mstar,utmi = <0x42>;
				mstar,usbc = <0x43>;
				status = "okay";
				vbus-supply = <0x44>;
				phandle = <0x45>;
			};

			uhc@285000 {
				compatible = "mstar,msc313-ehci";
				reg = <0x285000 0x200>;
				interrupts-extended = <0x0e 0x00 0x21 0x04>;
				phys = <0x45 0x00>;
				phy-names = "usb";
				mstar,usbc = <0x43>;
				status = "okay";
			};

			dphy@2a5000 {
				compatible = "sstar,ssd20xd-dphy";
				reg = <0x2a5000 0x200>;
				#phy-cells = <0x00>;
				phandle = <0x47>;
			};

			video-codec@344800 {
				compatible = "sstar,ssd20xd-vdec";
				reg = <0x344800 0x800>;
				clocks = <0x0d 0x01 0x14 0x00 0x0d 0x01 0x15 0x00 0x0d 0x01 0x16 0x00 0x0d 0x01 0x17 0x00>;
				interrupts-extended = <0x0e 0x00 0x15 0x04>;
				interconnects = <0x11 0x00>;
				interconnect-names = "dma-mem";
				status = "disabled";
			};

			phy@2a4a00 {
				#phy-cells = <0x00>;
				compatible = "sstar,ssd203d-sata-phy";
				reg = <0x2a4a00 0x600>;
				phandle = <0x46>;
			};

			ahci@345000 {
				compatible = "generic-ahci";
				reg = <0x345000 0x1000>;
				interrupts-extended = <0x0e 0x00 0x12 0x04>;
				clocks = <0x0d 0x01 0x13 0x00>;
				phy-names = "sata-phy";
				phys = <0x46>;
				status = "disabled";
			};

			dsi@345200 {
				compatible = "sstar,ssd20xd-dsi";
				reg = <0x345200 0x400>;
				interrupts-extended = <0x0e 0x00 0x39 0x04>;
				phy-names = "dphy";
				phys = <0x47>;
				clock-names = "engine\0digital\0hs";
				clocks = <0x08 0x08 0x08>;
				status = "disabled";
				phandle = <0x40>;

				ports {
					#address-cells = <0x01>;
					#size-cells = <0x00>;

					port@0 {
						reg = <0x00>;

						endpoint {
						};
					};

					port@1 {
						reg = <0x01>;

						endpoint {
							remote-endpoint = <0x48>;
						};
					};
				};
			};

			emac@2a2800 {
				#address-cells = <0x01>;
				#size-cells = <0x00>;
				compatible = "mstar,msc313-emac";
				interrupt-parent = <0x0e>;
				interrupts = <0x00 0x34 0x04>;
				reg = <0x2a2800 0x800>;
				clock-names = "pclk\0hclk\0tx_clk\0rx_clk\0tx_ref\0rx_ref";
				clocks = <0x0d 0x01 0x0b 0x00 0x0d 0x01 0x0b 0x00 0x33 0x0d 0x33 0x09 0x33 0x0f 0x33 0x0b>;
				local-mac-address = [00 00 00 00 00 00];
				status = "disabled";
				assigned-clocks = <0x33 0x08 0x33 0x0c>;
				assigned-clock-parents = <0x2d 0x2d>;
			};
		};

		csi@1f240800 {
			reg = <0x1f240800 0x200>;
			interrupts-extended = <0x0e 0x00 0x20 0x04>;
		};

		usb@0 {
			#phy-cells = <0x01>;
			compatible = "mstar,msc313-usb-phy";
			clocks = <0x08>;
			mstar,utmi = <0x49>;
			mstar,usbc = <0x2f>;
			interrupts-extended = <0x0e 0x00 0x1e 0x04>;
			status = "okay";
			phandle = <0x2e>;
		};

		usbphy@1 {
			#phy-cells = <0x01>;
			compatible = "mstar,msc313-usb-phy";
			clocks = <0x08>;
			mstar,utmi = <0x4a>;
			mstar,usbc = <0x31>;
			status = "disabled";
			phandle = <0x30>;
		};

		sram@a0000000 {
			compatible = "mmio-sram";
			reg = <0xa0000000 0x10000>;
		};

		mcm@1f226000 {
			compatible = "mstar,msc313-mcm";
			reg = <0x1f226000 0x08>;
		};

		mcm@1f226400 {
			compatible = "mstar,msc313-mcm";
			reg = <0x1f226400 0x08>;
		};

		gates@1f226640 {
		};

		mcm@1f226800 {
			compatible = "mstar,msc313-mcm";
			reg = <0x1f226800 0xa8>;
		};

		pwm@1f001da0 {
			compatible = "mstar,msc313-pwm";
			reg = <0x1f001da0 0x0c>;
			#pwm-cells = <0x02>;
			clocks = <0x08>;
			status = "disabled";
		};

		syscon@1f006200 {
			compatible = "syscon";
			reg = <0x1f006200 0x600>;
			phandle = <0x39>;
		};

		cmdq@1f224000 {
			reg = <0x1f224000 0x200>;
			compatible = "mstar,msc313-cmdq";
			interrupts-extended = <0x0e 0x00 0x11 0x04>;
			clocks = <0x0d 0x01 0x00 0x00>;
		};

		jpe@0x1f264000 {
			reg = <0x1f264000 0x100>;
			interrupts = <0x0e 0x00 0x1d 0x04>;
			clocks = <0x0d 0x01 0x10 0x00>;
		};

		mfe@1f264800 {
			reg = <0x1f264800 0x200>;
			interrupts = <0x1c 0x04>;
		};

		vhe@1f265000 {
			reg = <0x1f265200 0x200 0x1f265000 0x100>;
			interrupts = <0x15 0x04>;
		};

		emmc@1f280400 {
			interrupts = <0x00 0x12 0x04>;
		};

		bc@1f284400 {
			reg = <0x1f284400 0x200>;
		};

		fakephy@0 {
			compatible = "usb-nop-xceiv";
			#phy-cells = <0x00>;
			phandle = <0x4b>;
		};

		otg@1f284a00 {
			compatible = "mstar,msc313-musb";
			reg = <0x1f284a00 0x200>;
			interrupt-names = "mc";
			interrupts-extended = <0x0e 0x00 0x20 0x04>;
			phys = <0x4b>;
			mstar,usbc = <0x2f>;
			clock-names = "udc";
			clocks = <0x08>;
			status = "disabled";
		};
	};

	opp_table0 {
		compatible = "operating-points-v2";
		opp-shared;
		phandle = <0x03>;

		opp-240000000 {
			opp-hz = <0x00 0xe4e1c00>;
			opp-microvolt = <0xe7ef0>;
			clock-latency-ns = <0x493e0>;
		};

		opp-400000000 {
			opp-hz = <0x00 0x17d78400>;
			opp-microvolt = <0xe7ef0>;
			clock-latency-ns = <0x493e0>;
		};

		opp-600000000 {
			opp-hz = <0x00 0x23c34600>;
			opp-microvolt = <0xe7ef0>;
			clock-latency-ns = <0x493e0>;
		};

		opp-800000000 {
			opp-hz = <0x00 0x2faf0800>;
			opp-microvolt = <0xf4240>;
			clock-latency-ns = <0x493e0>;
		};

		opp-1008000000 {
			opp-hz = <0x00 0x3c14dc00>;
			opp-microvolt = <0xf4240>;
			clock-latency-ns = <0x493e0>;
		};

		opp-108000000 {
			opp-hz = <0x00 0x405f7e00>;
			opp-microvolt = <0xf4240>;
			clock-latency-ns = <0x493e0>;
		};

		opp-1188000000 {
			opp-hz = <0x00 0x46cf7100>;
			opp-microvolt = <0xf4240>;
			clock-latency-ns = <0x493e0>;
		};

		opp-1296000000 {
			opp-hz = <0x00 0x4d3f6400>;
			opp-microvolt = <0xf4240>;
			clock-latency-ns = <0x493e0>;
		};

		opp-1350000000 {
			opp-hz = <0x00 0x50775d80>;
			opp-microvolt = <0xf4240>;
			clock-latency-ns = <0x493e0>;
			turbo-mode;
		};

		opp-1404000000 {
			opp-hz = <0x00 0x53af5700>;
			opp-microvolt = <0xf4240>;
			clock-latency-ns = <0x493e0>;
			turbo-mode;
		};

		opp-1458000000 {
			opp-hz = <0x00 0x56e75080>;
			opp-microvolt = <0xf4240>;
			clock-latency-ns = <0x493e0>;
			turbo-mode;
		};

		opp-1512000000 {
			opp-hz = <0x00 0x5a1f4a00>;
			opp-microvolt = <0xf4240>;
			clock-latency-ns = <0x493e0>;
			turbo-mode;
		};

		opp-1600000000 {
			opp-hz = <0x00 0x5f5e1000>;
			opp-microvolt = <0xf4240>;
			clock-latency-ns = <0x493e0>;
			turbo-mode;
		};

		opp-1700000000 {
			opp-hz = <0x00 0x6553f100>;
			opp-microvolt = <0xf4240>;
			clock-latency-ns = <0x493e0>;
			turbo-mode;
		};
	};

	timer_clk {
		#clock-cells = <0x00>;
		compatible = "fixed-clock";
		clock-frequency = <0x19bfcc00>;
		phandle = <0x1b>;
	};

	memory {
		device_type = "memory";
		reg = <0x20000000 0x8000000>;
	};

	aliases {
		serial0 = "/soc/bus@1f000000/serial@221000";
	};

	chosen {
		stdout-path = "serial0:115200n8";
	};

	leds {
		compatible = "gpio-leds";

		led-0 {
			color = <0x00>;
			function = "indicator";
			gpios = <0x4c 0x2a 0x01>;
			linux,default-trigger = "activity";
		};

		led-1 {
			color = <0x01>;
			function = "indicator";
			gpios = <0x4c 0x2b 0x01>;
			linux,default-trigger = "heartbeat";
		};
	};

	gpio-keys {
		compatible = "gpio-keys-polled";
		poll-interval = <0x64>;

		button {
			label = "button";
			gpios = <0x4c 0x2c 0x01>;
			linux,code = <0x100>;
		};
	};

	regulator-vcc-core {
		compatible = "regulator-fixed";
		regulator-name = "vcc_core";
		regulator-min-microvolt = <0xe7ef0>;
		regulator-max-microvolt = <0xe7ef0>;
		regulator-boot-on;
		phandle = <0x04>;
	};

	regulator-vcc-io {
		compatible = "regulator-fixed";
		regulator-name = "vcc_io";
		regulator-min-microvolt = <0x325aa0>;
		regulator-max-microvolt = <0x325aa0>;
		regulator-boot-on;
		phandle = <0x36>;
	};

	regulator-vcc-dram {
		compatible = "regulator-fixed";
		regulator-name = "vcc_dram";
		regulator-min-microvolt = <0x16e360>;
		regulator-max-microvolt = <0x16e360>;
		regulator-boot-on;
		phandle = <0x25>;
	};

	regulator-vcc-wifi {
		compatible = "regulator-fixed";
		regulator-name = "vcc_wifi";
		regulator-min-microvolt = <0x325aa0>;
		regulator-max-microvolt = <0x325aa0>;
		gpios = <0x4c 0x38 0x00>;
		phandle = <0x44>;
	};
};
